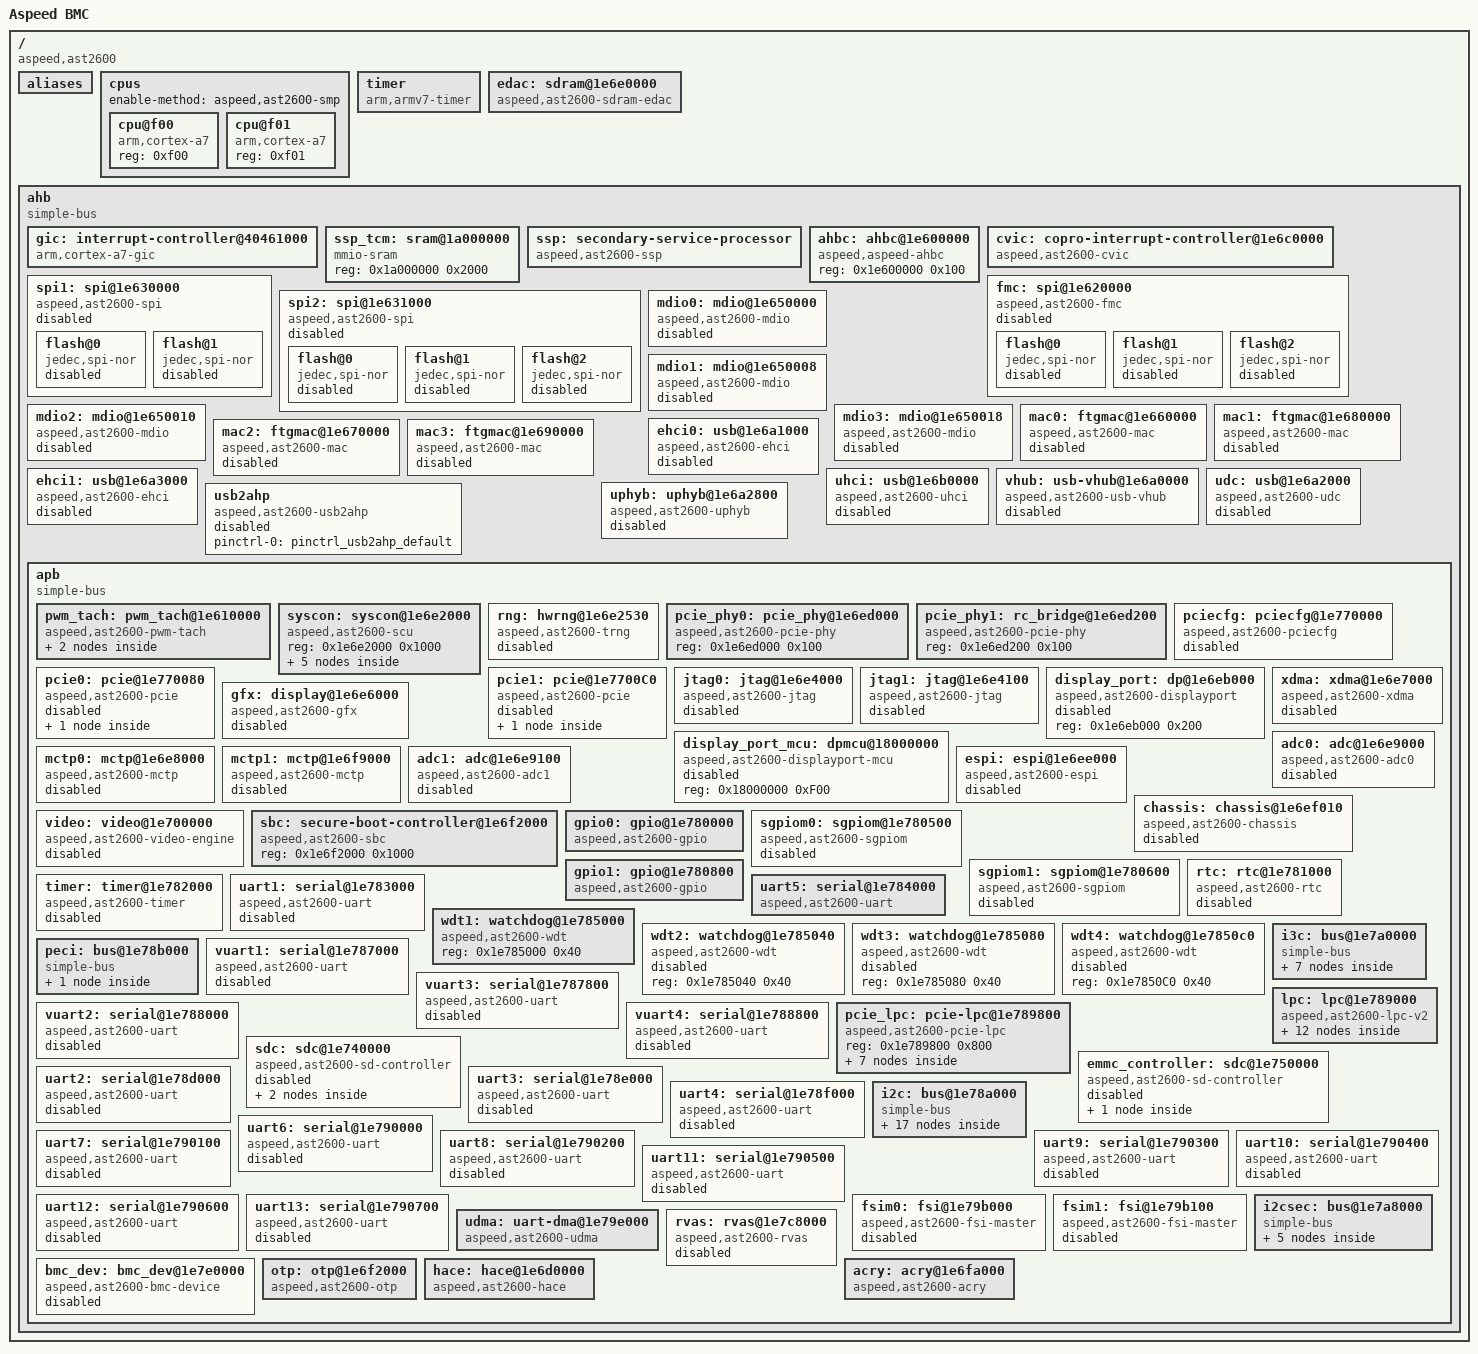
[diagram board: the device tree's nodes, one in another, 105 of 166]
// SPDX-License-Identifier: GPL-2.0-or-later
// Copyright 2019 IBM Corp.

#include <dt-bindings/interrupt-controller/arm-gic.h>
#include <dt-bindings/interrupt-controller/aspeed-scu-ic.h>
#include <dt-bindings/clock/ast2600-clock.h>

/ {
	model = "Aspeed BMC";
	compatible = "aspeed,ast2600";
	#address-cells = <1>;
	#size-cells = <1>;
	interrupt-parent = <&gic>;

	aliases {
		i3c0 = &i3c0;
		i3c1 = &i3c1;
		i3c2 = &i3c2;
		i3c3 = &i3c3;
		i3c4 = &i3c4;
		i3c5 = &i3c5;
		i2c0 = &i2c0;
		i2c1 = &i2c1;
		i2c2 = &i2c2;
		i2c3 = &i2c3;
		i2c4 = &i2c4;
		i2c5 = &i2c5;
		i2c6 = &i2c6;
		i2c7 = &i2c7;
		i2c8 = &i2c8;
		i2c9 = &i2c9;
		i2c10 = &i2c10;
		i2c11 = &i2c11;
		i2c12 = &i2c12;
		i2c13 = &i2c13;
		i2c14 = &i2c14;
		i2c15 = &i2c15;
		serial0 = &uart1;
		serial1 = &uart2;
		serial2 = &uart3;
		serial3 = &uart4;
		serial4 = &uart5;
		serial5 = &uart6;
		serial6 = &uart7;
		serial7 = &uart8;
		serial8 = &uart9;
		serial9 = &uart10;
		serial10 = &uart11;
		serial11 = &uart12;
		serial12 = &uart13;
		serial13 = &vuart1;
		serial14 = &vuart2;
		serial15 = &vuart3;
		serial16 = &vuart4;
	};


	cpus {
		#address-cells = <1>;
		#size-cells = <0>;
		enable-method = "aspeed,ast2600-smp";

		cpu@f00 {
			compatible = "arm,cortex-a7";
			device_type = "cpu";
			reg = <0xf00>;
		};

		cpu@f01 {
			compatible = "arm,cortex-a7";
			device_type = "cpu";
			reg = <0xf01>;
		};
	};

	timer {
		compatible = "arm,armv7-timer";
		interrupt-parent = <&gic>;
		interrupts = <GIC_PPI 13 (GIC_CPU_MASK_SIMPLE(2) | IRQ_TYPE_LEVEL_LOW)>,
			     <GIC_PPI 14 (GIC_CPU_MASK_SIMPLE(2) | IRQ_TYPE_LEVEL_LOW)>,
			     <GIC_PPI 11 (GIC_CPU_MASK_SIMPLE(2) | IRQ_TYPE_LEVEL_LOW)>,
			     <GIC_PPI 10 (GIC_CPU_MASK_SIMPLE(2) | IRQ_TYPE_LEVEL_LOW)>;
		arm,cpu-registers-not-fw-configured;
		always-on;
	};

	edac: sdram@1e6e0000 {
		compatible = "aspeed,ast2600-sdram-edac", "syscon";
		reg = <0x1e6e0000 0x174>;
		interrupts = <GIC_SPI 0 IRQ_TYPE_LEVEL_HIGH>;
	};

	ahb {
		compatible = "simple-bus";
		#address-cells = <1>;
		#size-cells = <1>;
		device_type = "soc";
		ranges;

		gic: interrupt-controller@40461000 {
			compatible = "arm,cortex-a7-gic";
			interrupts = <GIC_PPI 9 (GIC_CPU_MASK_SIMPLE(2) | IRQ_TYPE_LEVEL_HIGH)>;
			#interrupt-cells = <3>;
			interrupt-controller;
			interrupt-parent = <&gic>;
			reg = <0x40461000 0x1000>,
			    <0x40462000 0x1000>,
			    <0x40464000 0x2000>,
			    <0x40466000 0x2000>;
		};

		ssp_tcm: sram@1a000000 {
			compatible = "mmio-sram";
			reg = <0x1a000000 0x2000>;
		};

		ssp: secondary-service-processor {
			compatible = "aspeed,ast2600-ssp";
			#address-cells = <2>;
			#size-cells = <0>;
			interrupts =	<GIC_SPI 182 IRQ_TYPE_LEVEL_HIGH>,
					<GIC_SPI 183 IRQ_TYPE_LEVEL_HIGH>,
					<GIC_SPI 184 IRQ_TYPE_LEVEL_HIGH>,
					<GIC_SPI 185 IRQ_TYPE_LEVEL_HIGH>,
					<GIC_SPI 186 IRQ_TYPE_LEVEL_HIGH>,
					<GIC_SPI 187 IRQ_TYPE_LEVEL_HIGH>,
					<GIC_SPI 188 IRQ_TYPE_LEVEL_HIGH>,
					<GIC_SPI 189 IRQ_TYPE_LEVEL_HIGH>,
					<GIC_SPI 190 IRQ_TYPE_LEVEL_HIGH>,
					<GIC_SPI 191 IRQ_TYPE_LEVEL_HIGH>,
					<GIC_SPI 192 IRQ_TYPE_LEVEL_HIGH>,
					<GIC_SPI 193 IRQ_TYPE_LEVEL_HIGH>,
					<GIC_SPI 194 IRQ_TYPE_LEVEL_HIGH>,
					<GIC_SPI 195 IRQ_TYPE_LEVEL_HIGH>,
					<GIC_SPI 196 IRQ_TYPE_LEVEL_HIGH>;
			aspeed,cvic = <&cvic>;
			aspeed,scu = <&syscon>;
		};

		ahbc: ahbc@1e600000 {
			compatible = "aspeed,aspeed-ahbc", "syscon";
			reg = < 0x1e600000 0x100>;
		};

		cvic: copro-interrupt-controller@1e6c0000 {
			compatible = "aspeed,ast2600-cvic", "aspeed-cvic";
			valid-sources = <0xffffffff>;
			copro-sw-interrupts = <1>;
			reg = <0x1e6c0000 0x80>;
		};

		fmc: spi@1e620000 {
#if 1
			reg = <0x1e620000 0xc4>,
				<0x20000000 0x10000000>;
			reg-names = "spi_ctrl_reg", "spi_mmap";
			compatible = "aspeed,ast2600-fmc";
#else
			/* reg : cs0 : cs1 : cs2 */
			reg = <0x1e620000 0x100
				0x20000000 0x200000
				0x24000000 0x200000
				0x28000000 0x200000>;
			compatible = "aspeed,ast2600-fmc-spi";
			number_of_chip_select = /bits/ 16 <3>;
#endif
			#address-cells = <1>;
			#size-cells = <0>;
			clocks = <&syscon ASPEED_CLK_AHB>;
			status = "disabled";
			interrupts = <GIC_SPI 39 IRQ_TYPE_LEVEL_HIGH>;
			num-cs = <3>;
			flash@0 {
				reg = < 0 >;
				compatible = "jedec,spi-nor";
				spi-max-frequency = <50000000>;
				spi-rx-bus-width = <2>;
				status = "disabled";
			};
			flash@1 {
				reg = < 1 >;
				compatible = "jedec,spi-nor";
				spi-max-frequency = <50000000>;
				spi-rx-bus-width = <2>;
				status = "disabled";
			};
			flash@2 {
				reg = < 2 >;
				compatible = "jedec,spi-nor";
				spi-max-frequency = <50000000>;
				spi-rx-bus-width = <2>;
				status = "disabled";
			};
		};

		spi1: spi@1e630000 {
#if 1
			reg = <0x1e630000 0xc4>,
				<0x30000000 0x10000000>;
			reg-names = "spi_ctrl_reg", "spi_mmap";
			compatible = "aspeed,ast2600-spi";
#else
			/* reg : cs0 : cs1 */
			reg = <0x1e630000 0x100
				0x30000000 0x200000
				0x32000000 0x200000>;
			compatible = "aspeed,ast2600-fmc-spi";
			number_of_chip_select = /bits/ 16 <2>;
#endif
			#address-cells = <1>;
			#size-cells = <0>;
			clocks = <&syscon ASPEED_CLK_AHB>;
			num-cs = <2>;
			interrupts = <GIC_SPI 65 IRQ_TYPE_LEVEL_HIGH>;
			status = "disabled";
			flash@0 {
				reg = < 0 >;
				compatible = "jedec,spi-nor";
				spi-max-frequency = <50000000>;
				spi-rx-bus-width = <2>;
				status = "disabled";
			};
			flash@1 {
				reg = < 1 >;
				compatible = "jedec,spi-nor";
				spi-max-frequency = <50000000>;
				spi-rx-bus-width = <2>;
				status = "disabled";
			};
		};

		spi2: spi@1e631000 {
#if 1
			reg = < 0x1e631000 0xc4>,
				<0x50000000 0x10000000>;
			reg-names = "spi_ctrl_reg", "spi_mmap";
			compatible = "aspeed,ast2600-spi";
#else
			/* reg : cs0 : cs1 */
			reg = <0x1e631000 0x100
				0x50000000 0x200000
				0x52000000 0x200000
				0x54000000 0x200000>;
			compatible = "aspeed,ast2600-fmc-spi";
			number_of_chip_select = /bits/ 16 <3>;
#endif
			#address-cells = <1>;
			#size-cells = <0>;
			clocks = <&syscon ASPEED_CLK_AHB>;
			num-cs = <3>;
			interrupts = <GIC_SPI 65 IRQ_TYPE_LEVEL_HIGH>;
			status = "disabled";
			flash@0 {
				reg = < 0 >;
				compatible = "jedec,spi-nor";
				spi-max-frequency = <50000000>;
				spi-rx-bus-width = <2>;
				status = "disabled";
			};
			flash@1 {
				reg = < 1 >;
				compatible = "jedec,spi-nor";
				spi-max-frequency = <50000000>;
				spi-rx-bus-width = <2>;
				status = "disabled";
			};
			flash@2 {
				reg = < 2 >;
				compatible = "jedec,spi-nor";
				spi-max-frequency = <50000000>;
				spi-rx-bus-width = <2>;
				status = "disabled";
			};
		};

		mdio0: mdio@1e650000 {
			compatible = "aspeed,ast2600-mdio";
			reg = <0x1e650000 0x8>;
			#address-cells = <1>;
			#size-cells = <0>;
			status = "disabled";
			pinctrl-names = "default";
			pinctrl-0 = <&pinctrl_mdio1_default>;
			resets = <&syscon ASPEED_RESET_MII>;
		};

		mdio1: mdio@1e650008 {
			compatible = "aspeed,ast2600-mdio";
			reg = <0x1e650008 0x8>;
			#address-cells = <1>;
			#size-cells = <0>;
			status = "disabled";
			pinctrl-names = "default";
			pinctrl-0 = <&pinctrl_mdio2_default>;
			resets = <&syscon ASPEED_RESET_MII>;
		};

		mdio2: mdio@1e650010 {
			compatible = "aspeed,ast2600-mdio";
			reg = <0x1e650010 0x8>;
			#address-cells = <1>;
			#size-cells = <0>;
			status = "disabled";
			pinctrl-names = "default";
			pinctrl-0 = <&pinctrl_mdio3_default>;
			resets = <&syscon ASPEED_RESET_MII>;
		};

		mdio3: mdio@1e650018 {
			compatible = "aspeed,ast2600-mdio";
			reg = <0x1e650018 0x8>;
			#address-cells = <1>;
			#size-cells = <0>;
			status = "disabled";
			pinctrl-names = "default";
			pinctrl-0 = <&pinctrl_mdio4_default>;
			resets = <&syscon ASPEED_RESET_MII>;
		};

		mac0: ftgmac@1e660000 {
			compatible = "aspeed,ast2600-mac", "faraday,ftgmac100";
			reg = <0x1e660000 0x180>;
			#address-cells = <1>;
			#size-cells = <0>;
			interrupts = <GIC_SPI 2 IRQ_TYPE_LEVEL_HIGH>;
			clocks = <&syscon ASPEED_CLK_GATE_MAC1CLK>;
			resets = <&syscon ASPEED_RESET_MAC1>;
			status = "disabled";
		};

		mac1: ftgmac@1e680000 {
			compatible = "aspeed,ast2600-mac", "faraday,ftgmac100";
			reg = <0x1e680000 0x180>;
			#address-cells = <1>;
			#size-cells = <0>;
			interrupts = <GIC_SPI 3 IRQ_TYPE_LEVEL_HIGH>;
			clocks = <&syscon ASPEED_CLK_GATE_MAC2CLK>;
			resets = <&syscon ASPEED_RESET_MAC2>;
			status = "disabled";
		};

		mac2: ftgmac@1e670000 {
			compatible = "aspeed,ast2600-mac", "faraday,ftgmac100";
			reg = <0x1e670000 0x180>;
			#address-cells = <1>;
			#size-cells = <0>;
			interrupts = <GIC_SPI 32 IRQ_TYPE_LEVEL_HIGH>;
			clocks = <&syscon ASPEED_CLK_GATE_MAC3CLK>;
			resets = <&syscon ASPEED_RESET_MAC3>;
			status = "disabled";
		};

		mac3: ftgmac@1e690000 {
			compatible = "aspeed,ast2600-mac", "faraday,ftgmac100";
			reg = <0x1e690000 0x180>;
			#address-cells = <1>;
			#size-cells = <0>;
			interrupts = <GIC_SPI 33 IRQ_TYPE_LEVEL_HIGH>;
			clocks = <&syscon ASPEED_CLK_GATE_MAC4CLK>;
			resets = <&syscon ASPEED_RESET_MAC4>;
			status = "disabled";
		};

		ehci0: usb@1e6a1000 {
			compatible = "aspeed,ast2600-ehci", "generic-ehci";
			reg = <0x1e6a1000 0x100>;
			interrupts = <GIC_SPI 5 IRQ_TYPE_LEVEL_HIGH>;
			clocks = <&syscon ASPEED_CLK_GATE_USBPORT1CLK>;
			pinctrl-names = "default";
			pinctrl-0 = <&pinctrl_usb2ah_default>;
			status = "disabled";
		};

		ehci1: usb@1e6a3000 {
			compatible = "aspeed,ast2600-ehci", "generic-ehci";
			reg = <0x1e6a3000 0x100>;
			interrupts = <GIC_SPI 9 IRQ_TYPE_LEVEL_HIGH>;
			clocks = <&syscon ASPEED_CLK_GATE_USBPORT2CLK>;
			pinctrl-names = "default";
			pinctrl-0 = <&pinctrl_usb2bh_default>;
			status = "disabled";
		};

		uhci: usb@1e6b0000 {
			compatible = "aspeed,ast2600-uhci", "generic-uhci";
			reg = <0x1e6b0000 0x100>;
			interrupts = <GIC_SPI 10 IRQ_TYPE_LEVEL_HIGH>;
			#ports = <2>;
			clocks = <&syscon ASPEED_CLK_GATE_USBUHCICLK>;
			status = "disabled";
			/*
			 * No default pinmux, it will follow EHCI, use an
			 * explicit pinmux override if EHCI is not enabled.
			 */
		};

		vhub: usb-vhub@1e6a0000 {
			compatible = "aspeed,ast2600-usb-vhub";
			reg = <0x1e6a0000 0x350>;
			interrupts = <GIC_SPI 5 IRQ_TYPE_LEVEL_HIGH>;
			clocks = <&syscon ASPEED_CLK_GATE_USBPORT1CLK>;
			aspeed,vhub-downstream-ports = <7>;
			aspeed,vhub-generic-endpoints = <21>;
			pinctrl-names = "default";
			pinctrl-0 = <&pinctrl_usb2ad_default>;
			status = "disabled";
		};

		usb2ahp: usb2ahp {
			compatible = "aspeed,ast2600-usb2ahp";
			pinctrl-names = "default";
			pinctrl-0 = <&pinctrl_usb2ahp_default>;
			status = "disabled";
		};

		udc: usb@1e6a2000 {
			compatible = "aspeed,ast2600-udc";
			reg = <0x1e6a2000 0x300>;
			interrupts = <GIC_SPI 9 IRQ_TYPE_LEVEL_HIGH>;
			clocks = <&syscon ASPEED_CLK_GATE_USBPORT2CLK>;
			pinctrl-names = "default";
			pinctrl-0 = <&pinctrl_usb2bd_default>;
			status = "disabled";
		};

		uphyb: uphyb@1e6a2800 {
			compatible = "aspeed,ast2600-uphyb";
			reg = <0x1e6a2800 0x10>;
			ctrl = <0x0 0x100>;	/* <offset, value> */
			aspeed,scu = <&syscon>;
			status = "disabled";
		};

		apb {
			compatible = "simple-bus";
			#address-cells = <1>;
			#size-cells = <1>;
			ranges;

			pwm_tach: pwm_tach@1e610000 {
				compatible = "aspeed,ast2600-pwm-tach", "simple-mfd", "syscon";
				reg = <0x1e610000 0x100>;
				clocks = <&syscon ASPEED_CLK_AHB>;
				resets = <&syscon ASPEED_RESET_PWM>;

				pwm: pwm {
					compatible = "aspeed,ast2600-pwm";
					#pwm-cells = <3>;
					#address-cells = <1>;
					#size-cells = <0>;
					status = "disabled";
				};

				tach: tach {
					compatible = "aspeed,ast2600-tach";
					#address-cells = <1>;
					#size-cells = <0>;
					status = "disabled";
				};
			};

			syscon: syscon@1e6e2000 {
				compatible = "aspeed,ast2600-scu", "syscon", "simple-mfd";
				reg = <0x1e6e2000 0x1000>;
				ranges = <0 0x1e6e2000 0x1000>;
				#address-cells = <1>;
				#size-cells = <1>;
				#clock-cells = <1>;
				#reset-cells = <1>;

				pinctrl: pinctrl {
					compatible = "aspeed,ast2600-pinctrl";
				};

				silicon-id@14 {
					compatible = "aspeed,ast2600-silicon-id", "aspeed,silicon-id";
					reg = <0x14 0x4 0x5b0 0x8>;
				};

				smp-memram@180 {
					compatible = "aspeed,ast2600-smpmem";
					reg = <0x180 0x40>;
				};

				scu_ic0: interrupt-controller@560 {
					#interrupt-cells = <1>;
					compatible = "aspeed,ast2600-scu-ic0";
					reg = <0x560 0x4>;
					interrupts = <GIC_SPI 12 IRQ_TYPE_LEVEL_HIGH>;
					interrupt-controller;
				};

				scu_ic1: interrupt-controller@570 {
					#interrupt-cells = <1>;
					compatible = "aspeed,ast2600-scu-ic1";
					reg = <0x570 0x4>;
					interrupts = <GIC_SPI 41 IRQ_TYPE_LEVEL_HIGH>;
					interrupt-controller;
				};
			};

			rng: hwrng@1e6e2530 {
				compatible = "aspeed,ast2600-trng";
				reg = <0x1e6e2520 0x20>;
				aspeed,scu = <&syscon>;
				status = "disabled";
			};

			pcie_phy0: pcie_phy@1e6ed000 {
				compatible = "aspeed,ast2600-pcie-phy", "syscon";
				reg = <0x1e6ed000 0x100>;
			};

			pcie_phy1: rc_bridge@1e6ed200 {
				compatible = "aspeed,ast2600-pcie-phy", "syscon";
				reg = <0x1e6ed200 0x100>;
			};

			pciecfg: pciecfg@1e770000 {
				compatible = "aspeed,ast2600-pciecfg", "syscon";
				reg = <0x1e770000 0x80>;
				resets = <&syscon ASPEED_RESET_H2X>, <&syscon ASPEED_RESET_PCIE_DEV_O>, <&syscon ASPEED_RESET_PCIE_RC_O>;
				reset-names = "h2x", "rc_low", "rc_high";
				aspeed,ahbc = <&ahbc>;
				aspeed,pcie0 = <&pcie0>;
				aspeed,pcie1 = <&pcie1>;

				status = "disabled";
			};

			pcie0: pcie@1e770080 {
				compatible = "aspeed,ast2600-pcie";
				device_type = "pci";
				reg = <0x1e770080 0x40>;
				linux,pci-domain = <0>;
				#address-cells = <3>;
				#size-cells = <2>;
				interrupts = <GIC_SPI 167 IRQ_TYPE_LEVEL_HIGH>;
				bus-range = <0x00 0x7f>;
				ranges = <0x01000000 0 0x00000000 0x00000000 0x0 0x08000   /* I/O */
					0x02000000 0x0 0x60000000 0x60000000 0 0x10000000>; /* memory */

				status = "disabled";

				resets = <&syscon ASPEED_RESET_PCIE_DEV_O>;
				pinctrl-names = "default";
				pinctrl-0 = <&pinctrl_pcierc0_default>;

				#interrupt-cells = <1>;
				msi-parent = <&pcie0>;
				msi_address = <0x1e770058>;
				pciephy = <&pcie_phy0>;
				interrupt-map-mask = <0 0 0 7>;
				interrupt-map = <0 0 0 1 &pcie_intc0 0>,
						<0 0 0 2 &pcie_intc0 1>,
						<0 0 0 3 &pcie_intc0 2>,
						<0 0 0 4 &pcie_intc0 3>;
				pcie_intc0: interrupt-controller {
					interrupt-controller;
					#address-cells = <0>;
					#interrupt-cells = <1>;
				};
			};

			pcie1: pcie@1e7700C0 {
				compatible = "aspeed,ast2600-pcie";
				device_type = "pci";
				reg = <0x1e7700C0 0x40>;
				linux,pci-domain = <1>;
				#address-cells = <3>;
				#size-cells = <2>;
				interrupts = <GIC_SPI 168 IRQ_TYPE_LEVEL_HIGH>;
				bus-range = <0x80 0xff>;

				ranges = <0x01000000 0 0x00018000 0x00018000 0x0 0x08000
					0x02000000 0x0 0x70000000 0x70000000 0 0x10000000>; /* memory */

				status = "disabled";

				resets = <&syscon ASPEED_RESET_PCIE_RC_O>;
				pinctrl-names = "default";
				pinctrl-0 = <&pinctrl_pcierc1_default>;

				#interrupt-cells = <1>;
				msi-parent = <&pcie1>;
				msi_address = <0x1e77005C>;
				pciephy = <&pcie_phy1>;
				interrupt-map-mask = <0 0 0 7>;
				interrupt-map = <0 0 0 1 &pcie_intc1 0>,
						<0 0 0 2 &pcie_intc1 1>,
						<0 0 0 3 &pcie_intc1 2>,
						<0 0 0 4 &pcie_intc1 3>;
				pcie_intc1: interrupt-controller {
					interrupt-controller;
					#address-cells = <0>;
					#interrupt-cells = <1>;
				};
			};

			jtag0: jtag@1e6e4000 {
				compatible = "aspeed,ast2600-jtag";
				reg= <0x1e6e4000 0x20>;
				interrupts = <GIC_SPI 27 IRQ_TYPE_LEVEL_HIGH>;
				clocks = <&syscon ASPEED_CLK_AHB>;
				resets = <&syscon ASPEED_RESET_JTAG_MASTER>;
				status = "disabled";
			};

			jtag1: jtag@1e6e4100 {
				compatible = "aspeed,ast2600-jtag";
				reg= <0x1e6e4100 0x20>;
				interrupts = <GIC_SPI 53 IRQ_TYPE_LEVEL_HIGH>;
				clocks = <&syscon ASPEED_CLK_AHB>;
				resets = <&syscon ASPEED_RESET_JTAG_MASTER2>;
				pinctrl-names = "default";
				pinctrl-0 = <&pinctrl_jtagm_default>;
				status = "disabled";
			};

			display_port: dp@1e6eb000 {
				compatible = "aspeed,ast2600-displayport", "syscon";
				reg = <0x1e6eb000 0x200>;
				status = "disabled";
			};

			display_port_mcu: dpmcu@18000000 {
				compatible = "aspeed,ast2600-displayport-mcu", "syscon";
				reg = <0x18000000 0xF00>;
				status = "disabled";
			};

			gfx: display@1e6e6000 {
				compatible = "aspeed,ast2600-gfx", "syscon";
				reg = <0x1e6e6000 0x1000>;
				reg-io-width = <4>;
				clocks = <&syscon ASPEED_CLK_GATE_D1CLK>;
				resets = <&syscon ASPEED_RESET_CRT>,
				<&syscon ASPEED_RESET_GRAPHICS>;
				reset-names = "crt", "engine";
				syscon = <&syscon>;
				interrupts-extended = <&gic GIC_SPI 14 IRQ_TYPE_LEVEL_HIGH>,
				<&scu_ic0 ASPEED_AST2600_SCU_IC0_PCIE_PERST_LO_TO_HI>,
				<&scu_ic0 ASPEED_AST2600_SCU_IC0_PCIE_PERST_HI_TO_LO>;
				status = "disabled";
			};

			xdma: xdma@1e6e7000 {
				compatible = "aspeed,ast2600-xdma";
				reg = <0x1e6e7000 0x100>;
				clocks = <&syscon ASPEED_CLK_GATE_BCLK>;
				resets = <&syscon ASPEED_RESET_DEV_XDMA>, <&syscon ASPEED_RESET_RC_XDMA>;
				reset-names = "device", "root-complex";
				interrupts-extended = <&gic GIC_SPI 6 IRQ_TYPE_LEVEL_HIGH>,
						      <&scu_ic0 ASPEED_AST2600_SCU_IC0_PCIE_PERST_LO_TO_HI>;
				aspeed,pcie-device = "bmc";
				aspeed,scu = <&syscon>;
				status = "disabled";
			};

			mctp0: mctp@1e6e8000 {
				compatible = "aspeed,ast2600-mctp";
				reg = <0x1e6e8000 0x30>;
				interrupts-extended = <&gic GIC_SPI 26 IRQ_TYPE_LEVEL_HIGH>, <&scu_ic0 ASPEED_AST2600_SCU_IC0_PCIE_PERST_LO_TO_HI>;
				interrupt-names = "mctp", "pcie";
				resets = <&syscon ASPEED_RESET_DEV_MCTP>;
				aspeed,scu = <&syscon>;
				aspeed,pcieh = <&pcie_phy0>;
				status = "disabled";
			};

			mctp1: mctp@1e6f9000 {
				compatible = "aspeed,ast2600-mctp";
				reg = <0x1e6f9000 0x30>;
				interrupts-extended = <&scu_ic0 ASPEED_AST2600_SCU_IC0_PCIE_RCRST_LO_TO_HI>;
				interrupt-names = "pcie";
				pcie_rc;
				resets = <&syscon ASPEED_RESET_RC_MCTP>, <&syscon ASPEED_RESET_DEV_MCTP>;
				aspeed,scu = <&syscon>;
				aspeed,pcieh = <&pcie_phy1>;
				status = "disabled";
			};

			adc0: adc@1e6e9000 {
				compatible = "aspeed,ast2600-adc0";
				reg = <0x1e6e9000 0x100>;
				clocks = <&syscon ASPEED_CLK_APB2>;
				resets = <&syscon ASPEED_RESET_ADC>;
				interrupts = <GIC_SPI 46 IRQ_TYPE_LEVEL_HIGH>;
				#io-channel-cells = <1>;
				status = "disabled";
			};

			adc1: adc@1e6e9100 {
				compatible = "aspeed,ast2600-adc1";
				reg = <0x1e6e9100 0x100>;
				clocks = <&syscon ASPEED_CLK_APB2>;
				resets = <&syscon ASPEED_RESET_ADC>;
				interrupts = <GIC_SPI 46 IRQ_TYPE_LEVEL_HIGH>;
				#io-channel-cells = <1>;
				status = "disabled";
			};

			espi: espi@1e6ee000 {
				compatible = "aspeed,ast2600-espi";
				reg = <0x1e6ee000 0x1000>;
				interrupts = <GIC_SPI 42 IRQ_TYPE_LEVEL_HIGH>,
					     <GIC_SPI 108 IRQ_TYPE_LEVEL_HIGH>;
				clocks = <&syscon ASPEED_CLK_GATE_ESPICLK>;
				status = "disabled";
			};

			chassis: chassis@1e6ef010 {
				compatible = "aspeed,ast2600-chassis";
				reg = <0x1e6ef010 0x4>;
				interrupts = <GIC_SPI 149 IRQ_TYPE_LEVEL_HIGH>;
				status = "disabled";
			};

			video: video@1e700000 {
				compatible = "aspeed,ast2600-video-engine";
				reg = <0x1e700000 0x1000>;
				clocks = <&syscon ASPEED_CLK_GATE_VCLK>,
					 <&syscon ASPEED_CLK_GATE_ECLK>;
				clock-names = "vclk", "eclk";
				interrupts = <GIC_SPI 7 IRQ_TYPE_LEVEL_HIGH>;
				resets = <&syscon ASPEED_RESET_VIDEO>;
				status = "disabled";
			};

			sbc: secure-boot-controller@1e6f2000 {
				compatible = "aspeed,ast2600-sbc";
				reg = <0x1e6f2000 0x1000>;
			};

			gpio0: gpio@1e780000 {
				#gpio-cells = <2>;
				gpio-controller;
				compatible = "aspeed,ast2600-gpio";
				reg = <0x1e780000 0x400>;
				interrupts = <GIC_SPI 40 IRQ_TYPE_LEVEL_HIGH>;
				gpio-ranges = <&pinctrl 0 0 208>;
				ngpios = <208>;
				clocks = <&syscon ASPEED_CLK_APB2>;
				interrupt-controller;
				#interrupt-cells = <2>;
			};

			sgpiom0: sgpiom@1e780500 {
				#gpio-cells = <2>;
				gpio-controller;
				compatible = "aspeed,ast2600-sgpiom";
				reg = <0x1e780500 0x100>;
				interrupts = <GIC_SPI 51 IRQ_TYPE_LEVEL_HIGH>;
				clocks = <&syscon ASPEED_CLK_APB2>;
				interrupt-controller;
				bus-frequency = <12000000>;
				pinctrl-names = "default";
				pinctrl-0 = <&pinctrl_sgpm1_default>;
				status = "disabled";
			};

			sgpiom1: sgpiom@1e780600 {
				#gpio-cells = <2>;
				gpio-controller;
				compatible = "aspeed,ast2600-sgpiom";
				reg = <0x1e780600 0x100>;
				interrupts = <GIC_SPI 70 IRQ_TYPE_LEVEL_HIGH>;
				clocks = <&syscon ASPEED_CLK_APB2>;
				interrupt-controller;
				bus-frequency = <12000000>;
				pinctrl-names = "default";
				pinctrl-0 = <&pinctrl_sgpm2_default>;
				status = "disabled";
			};

			gpio1: gpio@1e780800 {
				#gpio-cells = <2>;
				gpio-controller;
				compatible = "aspeed,ast2600-gpio";
				reg = <0x1e780800 0x800>;
				interrupts = <GIC_SPI 11 IRQ_TYPE_LEVEL_HIGH>;
				gpio-ranges = <&pinctrl 0 208 36>;
				ngpios = <36>;
				clocks = <&syscon ASPEED_CLK_APB1>;
				interrupt-controller;
				#interrupt-cells = <2>;
			};

			rtc: rtc@1e781000 {
				compatible = "aspeed,ast2600-rtc";
				reg = <0x1e781000 0x18>;
				interrupts = <GIC_SPI 13 IRQ_TYPE_LEVEL_HIGH>;
				status = "disabled";
			};

			timer: timer@1e782000 {
				compatible = "aspeed,ast2600-timer";
				reg = <0x1e782000 0x90>;
				interrupts-extended = <&gic  GIC_SPI 16 IRQ_TYPE_LEVEL_HIGH>,
						<&gic  GIC_SPI 17 IRQ_TYPE_LEVEL_HIGH>,
						<&gic  GIC_SPI 18 IRQ_TYPE_LEVEL_HIGH>,
						<&gic  GIC_SPI 19 IRQ_TYPE_LEVEL_HIGH>,
						<&gic  GIC_SPI 20 IRQ_TYPE_LEVEL_HIGH>,
						<&gic  GIC_SPI 21 IRQ_TYPE_LEVEL_HIGH>,
						<&gic  GIC_SPI 22 IRQ_TYPE_LEVEL_HIGH>,
						<&gic  GIC_SPI 23 IRQ_TYPE_LEVEL_HIGH>;
				clocks = <&syscon ASPEED_CLK_APB1>;
				clock-names = "PCLK";
				status = "disabled";
                        };

			uart1: serial@1e783000 {
				compatible = "aspeed,ast2600-uart";
				reg = <0x1e783000 0x20>;
				reg-shift = <2>;
				reg-io-width = <4>;
				interrupts = <GIC_SPI 47 IRQ_TYPE_LEVEL_HIGH>;
				clocks = <&syscon ASPEED_CLK_GATE_UART1CLK>;
				resets = <&lpc_reset 4>;
				no-loopback-test;
				pinctrl-names = "default";
				pinctrl-0 = <&pinctrl_txd1_default &pinctrl_rxd1_default>;
				status = "disabled";
			};

			uart5: serial@1e784000 {
				compatible = "aspeed,ast2600-uart";
				reg = <0x1e784000 0x1000>;
				reg-shift = <2>;
				interrupts = <GIC_SPI 8 IRQ_TYPE_LEVEL_HIGH>;
				clocks = <&syscon ASPEED_CLK_GATE_UART5CLK>;
				no-loopback-test;
			};

			wdt1: watchdog@1e785000 {
				compatible = "aspeed,ast2600-wdt";
				reg = <0x1e785000 0x40>;
			};

			wdt2: watchdog@1e785040 {
				compatible = "aspeed,ast2600-wdt";
				reg = <0x1e785040 0x40>;
				status = "disabled";
			};

			wdt3: watchdog@1e785080 {
				compatible = "aspeed,ast2600-wdt";
				reg = <0x1e785080 0x40>;
				status = "disabled";
			};

			wdt4: watchdog@1e7850c0 {
				compatible = "aspeed,ast2600-wdt";
				reg = <0x1e7850C0 0x40>;
				status = "disabled";
			};

			i3c: bus@1e7a0000 {
				compatible = "simple-bus";
				#address-cells = <1>;
				#size-cells = <1>;
				ranges = <0 0x1e7a0000 0x8000>;
			};

			peci: bus@1e78b000 {
				compatible = "simple-bus";
				#address-cells = <1>;
				#size-cells = <1>;
				ranges = <0x0 0x1e78b000 0x100>;
			};

			vuart1: serial@1e787000 {
				compatible = "aspeed,ast2600-uart";
				reg = <0x1e787000 0x40>;
				interrupts = <GIC_SPI 147 IRQ_TYPE_LEVEL_HIGH>;
				clocks = <&syscon ASPEED_CLK_APB1>;
				virtual;
				status = "disabled";
			};

			vuart3: serial@1e787800 {
				compatible = "aspeed,ast2600-uart";
				reg = <0x1e787800 0x40>;
				interrupts = <GIC_SPI 180 IRQ_TYPE_LEVEL_HIGH>;
				clocks = <&syscon ASPEED_CLK_APB1>;
				virtual;
				status = "disabled";
			};

			vuart2: serial@1e788000 {
				compatible = "aspeed,ast2600-uart";
				reg = <0x1e788000 0x40>;
				interrupts = <GIC_SPI 148 IRQ_TYPE_LEVEL_HIGH>;
				clocks = <&syscon ASPEED_CLK_APB1>;
				virtual;
				status = "disabled";
			};

			vuart4: serial@1e788800 {
				compatible = "aspeed,ast2600-uart";
				reg = <0x1e788800 0x40>;
				interrupts = <GIC_SPI 181 IRQ_TYPE_LEVEL_HIGH>;
				clocks = <&syscon ASPEED_CLK_APB2>;
				virtual;
				status = "disabled";
			};

			lpc: lpc@1e789000 {
				compatible = "aspeed,ast2600-lpc-v2", "simple-mfd", "syscon";
				reg = <0x1e789000 0x1000>;
				reg-io-width = <4>;

				#address-cells = <1>;
				#size-cells = <1>;
				ranges = <0x0 0x1e789000 0x1000>;

				kcs1: kcs1@24 {
					compatible = "aspeed,ast2600-kcs-bmc";
					reg = <0x0 0x130>;
					interrupts = <GIC_SPI 138 IRQ_TYPE_LEVEL_HIGH>;
					clocks = <&syscon ASPEED_CLK_GATE_LCLK>;
					kcs_chan = <1>;
					status = "disabled";
				};

				kcs2: kcs2@28 {
					compatible = "aspeed,ast2600-kcs-bmc";
					reg = <0x0 0x130>;
					interrupts = <GIC_SPI 139 IRQ_TYPE_LEVEL_HIGH>;
					kcs_chan = <2>;
					status = "disabled";
				};

				kcs3: kcs3@2c {
					compatible = "aspeed,ast2600-kcs-bmc";
					reg = <0x0 0x130>;
					interrupts = <GIC_SPI 140 IRQ_TYPE_LEVEL_HIGH>;
					kcs_chan = <3>;
					status = "disabled";
				};

				kcs4: kcs4@114 {
					compatible = "aspeed,ast2600-kcs-bmc";
					reg = <0x0 0x130>;
					interrupts = <GIC_SPI 141 IRQ_TYPE_LEVEL_HIGH>;
					kcs_chan = <4>;
					status = "disabled";
				};

				lpc_ctrl: lpc-ctrl@80 {
					compatible = "aspeed,ast2600-lpc-ctrl";
					reg = <0x80 0x80>;
					clocks = <&syscon ASPEED_CLK_GATE_LCLK>;
					status = "disabled";
				};

				lpc_snoop: lpc-snoop@80 {
					compatible = "aspeed,ast2600-lpc-snoop";
					reg = <0x80 0x80>;
					interrupts = <GIC_SPI 144 IRQ_TYPE_LEVEL_HIGH>;
					status = "disabled";
				};

				lpc_pcc: lpc-pcc@0 {
					compatible = "aspeed,ast2600-lpc-pcc";
					reg = <0x0 0x140>;
					interrupts = <GIC_SPI 145 IRQ_TYPE_LEVEL_HIGH>;
					status = "disabled";
				};

				lhc: lhc@a0 {
					compatible = "aspeed,ast2600-lhc";
					reg = <0xa0 0x24 0xc8 0x8>;
				};

				lpc_reset: reset-controller@98 {
					compatible = "aspeed,ast2600-lpc-reset";
					reg = <0x98 0x4>;
					#reset-cells = <1>;
				};

				uart_routing: uart-routing@98 {
					compatible = "aspeed,ast2600-uart-routing";
					reg = <0x98 0x8>;
					status = "disabled";
				};

				ibt: ibt@140 {
					compatible = "aspeed,ast2600-ibt-bmc";
					reg = <0x140 0x18>;
					interrupts = <GIC_SPI 143 IRQ_TYPE_LEVEL_HIGH>;
					clocks = <&syscon ASPEED_CLK_GATE_LCLK>;
					status = "disabled";
				};

				mbox: mbox@200 {
					compatible = "aspeed,ast2600-mbox";
					reg = <0x200 0xc0>;
					interrupts = <GIC_SPI 54 IRQ_TYPE_LEVEL_HIGH>;
					status = "disabled";
				};
			};

			pcie_lpc: pcie-lpc@1e789800 {
				compatible = "aspeed,ast2600-pcie-lpc", "simple-mfd", "syscon";
				reg = <0x1e789800 0x800>;

				#address-cells = <1>;
				#size-cells = <1>;
				ranges = <0x0 0x1e789800 0x800>;

				pcie_kcs1: pcie-kcs1@0 {
					compatible = "aspeed,ast2600-kcs-bmc";
					reg = <0x0 0x130>;
					interrupts = <GIC_SPI 174 IRQ_TYPE_LEVEL_HIGH>;
					kcs_chan = <5>;
					status = "disabled";
				};

				pcie_kcs2: pcie-kcs2@0 {
					compatible = "aspeed,ast2600-kcs-bmc";
					reg = <0x0 0x130>;
					interrupts = <GIC_SPI 175 IRQ_TYPE_LEVEL_HIGH>;
					kcs_chan = <6>;
					status = "disabled";
				};

				pcie_kcs3: pcie-kcs3@0 {
					compatible = "aspeed,ast2600-kcs-bmc";
					reg = <0x0 0x130>;
					interrupts = <GIC_SPI 176 IRQ_TYPE_LEVEL_HIGH>;
					kcs_chan = <7>;
					status = "disabled";
				};

				pcie_kcs4: pcie-kcs4@0 {
					compatible = "aspeed,ast2600-kcs-bmc";
					reg = <0x0 0x130>;
					interrupts = <GIC_SPI 177 IRQ_TYPE_LEVEL_HIGH>;
					kcs_chan = <8>;
					status = "disabled";
				};

				pcie_snoop: pcie-snoop@80 {
					compatible = "aspeed,ast2600-lpc-snoop";
					reg = <0x80 0x80>;
					interrupts = <GIC_SPI 171 IRQ_TYPE_LEVEL_HIGH>;
					status = "disabled";
				};

				pcie_pcc: pcie-pcc@0 {
					compatible = "aspeed,ast2600-lpc-pcc";
					reg = <0x0 0x140>;
					interrupts = <GIC_SPI 173 IRQ_TYPE_LEVEL_HIGH>;
					status = "disabled";
				};

				pcie_ibt: pcie_ibt@140 {
					compatible = "aspeed,ast2600-ibt-bmc";
					reg = <0x140 0x18>;
					interrupts = <GIC_SPI 172 IRQ_TYPE_LEVEL_HIGH>;
					status = "disabled";
				};

			};

			sdc: sdc@1e740000 {
				compatible = "aspeed,ast2600-sd-controller";
				reg = <0x1e740000 0x100>;
				#address-cells = <1>;
				#size-cells = <1>;
				ranges = <0 0x1e740000 0x10000>;
				clocks = <&syscon ASPEED_CLK_GATE_SDCLK>;
				status = "disabled";

				sdhci0: sdhci@1e740100 {
					compatible = "aspeed,ast2600-sdhci", "sdhci";
					reg = <0x100 0x100>;
					interrupts = <GIC_SPI 43 IRQ_TYPE_LEVEL_HIGH>;
					sdhci,auto-cmd12;
					sd-uhs-sdr50;
					clocks = <&syscon ASPEED_CLK_SDIO>;
					pinctrl-names = "default";
					pinctrl-0 = <&pinctrl_sd1_default>;
					status = "disabled";
				};

				sdhci1: sdhci@1e740200 {
					compatible = "aspeed,ast2600-sdhci", "sdhci";
					reg = <0x200 0x100>;
					interrupts = <GIC_SPI 43 IRQ_TYPE_LEVEL_HIGH>;
					sdhci,auto-cmd12;
					sd-uhs-sdr50;
					clocks = <&syscon ASPEED_CLK_SDIO>;
					pinctrl-names = "default";
					pinctrl-0 = <&pinctrl_sd2_default>;
					status = "disabled";
				};
			};

			emmc_controller: sdc@1e750000 {
				compatible = "aspeed,ast2600-sd-controller";
				reg = <0x1e750000 0x100>;
				#address-cells = <1>;
				#size-cells = <1>;
				ranges = <0 0x1e750000 0x10000>;
				clocks = <&syscon ASPEED_CLK_GATE_EMMCCLK>;
				resets = <&syscon ASPEED_RESET_EMMC>;
				status = "disabled";

				emmc: sdhci@1e750100 {
					compatible = "aspeed,ast2600-emmc";
					reg = <0x100 0x100>;
					sdhci,auto-cmd12;
					interrupts = <GIC_SPI 15 IRQ_TYPE_LEVEL_HIGH>;
					clocks = <&syscon ASPEED_CLK_EMMC>;
					pinctrl-names = "default";
					pinctrl-0 = <&pinctrl_emmc_default>;
					status = "disabled";
				};
			};

			uart2: serial@1e78d000 {
				compatible = "aspeed,ast2600-uart";
				reg = <0x1e78d000 0x20>;
				interrupts = <GIC_SPI 48 IRQ_TYPE_LEVEL_HIGH>;
				clocks = <&syscon ASPEED_CLK_GATE_UART2CLK>;
				resets = <&lpc_reset 5>;
				pinctrl-names = "default";
				pinctrl-0 = <&pinctrl_txd2_default &pinctrl_rxd2_default>;
				no-loopback-test;
				status = "disabled";
			};

			uart3: serial@1e78e000 {
				compatible = "aspeed,ast2600-uart";
				reg = <0x1e78e000 0x20>;
				interrupts = <GIC_SPI 49 IRQ_TYPE_LEVEL_HIGH>;
				clocks = <&syscon ASPEED_CLK_GATE_UART3CLK>;
				resets = <&lpc_reset 6>;
				pinctrl-names = "default";
				pinctrl-0 = <&pinctrl_txd3_default &pinctrl_rxd3_default>;
				no-loopback-test;
				status = "disabled";
			};

			uart4: serial@1e78f000 {
				compatible = "aspeed,ast2600-uart";
				reg = <0x1e78f000 0x20>;
				interrupts = <GIC_SPI 50 IRQ_TYPE_LEVEL_HIGH>;
				clocks = <&syscon ASPEED_CLK_GATE_UART4CLK>;
				resets = <&lpc_reset 7>;
				pinctrl-names = "default";
				pinctrl-0 = <&pinctrl_txd4_default &pinctrl_rxd4_default>;
				no-loopback-test;
				status = "disabled";
			};

			i2c: bus@1e78a000 {
				compatible = "simple-bus";
				#address-cells = <1>;
				#size-cells = <1>;
				ranges = <0 0x1e78a000 0x1000>;
			};

			uart6: serial@1e790000 {
				compatible = "aspeed,ast2600-uart";
				reg = <0x1e790000 0x20>;
				interrupts = <GIC_SPI 57 IRQ_TYPE_LEVEL_HIGH>;
				clocks = <&syscon ASPEED_CLK_GATE_UART6CLK>;
				pinctrl-names = "default";
				pinctrl-0 = <&pinctrl_uart6_default>;
				no-loopback-test;
				status = "disabled";
			};

			uart7: serial@1e790100 {
				compatible = "aspeed,ast2600-uart";
				reg = <0x1e790100 0x20>;
				interrupts = <GIC_SPI 58 IRQ_TYPE_LEVEL_HIGH>;
				clocks = <&syscon ASPEED_CLK_GATE_UART7CLK>;
				pinctrl-names = "default";
				pinctrl-0 = <&pinctrl_uart7_default>;
				no-loopback-test;
				status = "disabled";
			};

			uart8: serial@1e790200 {
				compatible = "aspeed,ast2600-uart";
				reg = <0x1e790200 0x20>;
				interrupts = <GIC_SPI 59 IRQ_TYPE_LEVEL_HIGH>;
				clocks = <&syscon ASPEED_CLK_GATE_UART8CLK>;
				pinctrl-names = "default";
				pinctrl-0 = <&pinctrl_uart8_default>;
				no-loopback-test;
				status = "disabled";
			};

			uart9: serial@1e790300 {
				compatible = "aspeed,ast2600-uart";
				reg = <0x1e790300 0x20>;
				interrupts = <GIC_SPI 60 IRQ_TYPE_LEVEL_HIGH>;
				clocks = <&syscon ASPEED_CLK_GATE_UART9CLK>;
				pinctrl-names = "default";
				pinctrl-0 = <&pinctrl_uart9_default>;
				no-loopback-test;
				status = "disabled";
			};

			uart10: serial@1e790400 {
				compatible = "aspeed,ast2600-uart";
				reg = <0x1e790400 0x20>;
				interrupts = <GIC_SPI 61 IRQ_TYPE_LEVEL_HIGH>;
				clocks = <&syscon ASPEED_CLK_GATE_UART10CLK>;
				pinctrl-names = "default";
				pinctrl-0 = <&pinctrl_uart10_default>;
				no-loopback-test;
				status = "disabled";
			};

			uart11: serial@1e790500 {
				compatible = "aspeed,ast2600-uart";
				reg = <0x1e790500 0x20>;
				interrupts = <GIC_SPI 62 IRQ_TYPE_LEVEL_HIGH>;
				clocks = <&syscon ASPEED_CLK_GATE_UART11CLK>;
				pinctrl-names = "default";
				pinctrl-0 = <&pinctrl_uart11_default>;
				no-loopback-test;
				status = "disabled";
			};

			uart12: serial@1e790600 {
				compatible = "aspeed,ast2600-uart";
				reg = <0x1e790600 0x20>;
				interrupts = <GIC_SPI 63 IRQ_TYPE_LEVEL_HIGH>;
				clocks = <&syscon ASPEED_CLK_GATE_UART12CLK>;
				pinctrl-names = "default";
				pinctrl-0 = <&pinctrl_uart12g1_default>;
				no-loopback-test;
				status = "disabled";
			};

			uart13: serial@1e790700 {
				compatible = "aspeed,ast2600-uart";
				reg = <0x1e790700 0x20>;
				interrupts = <GIC_SPI 64 IRQ_TYPE_LEVEL_HIGH>;
				clocks = <&syscon ASPEED_CLK_GATE_UART13CLK>;
				pinctrl-names = "default";
				pinctrl-0 = <&pinctrl_uart13g1_default>;
				no-loopback-test;
				status = "disabled";
			};

			fsim0: fsi@1e79b000 {
				compatible = "aspeed,ast2600-fsi-master", "fsi-master";
				reg = <0x1e79b000 0x94>;
				interrupts = <GIC_SPI 100 IRQ_TYPE_LEVEL_HIGH>;
				pinctrl-names = "default";
				pinctrl-0 = <&pinctrl_fsi1_default>;
				clocks = <&syscon ASPEED_CLK_GATE_FSICLK>;
				status = "disabled";
			};

			fsim1: fsi@1e79b100 {
				compatible = "aspeed,ast2600-fsi-master", "fsi-master";
				reg = <0x1e79b100 0x94>;
				interrupts = <GIC_SPI 101 IRQ_TYPE_LEVEL_HIGH>;
				pinctrl-names = "default";
				pinctrl-0 = <&pinctrl_fsi2_default>;
				clocks = <&syscon ASPEED_CLK_GATE_FSICLK>;
				status = "disabled";
			};

			udma: uart-dma@1e79e000 {
				compatible = "aspeed,ast2600-udma";
				reg = <0x1e79e000 0x400>;
				interrupts = <GIC_SPI 56 IRQ_TYPE_LEVEL_HIGH>;
			};

			i2csec: bus@1e7a8000 {
				compatible = "simple-bus";
				#address-cells = <1>;
				#size-cells = <1>;
				ranges = <0 0x1e7a8000 0x1000>;
			};

			rvas: rvas@1e7c8000 {
				compatible = "aspeed,ast2600-rvas";
				reg = <0x1e7c8000 0x800 0x1e6ec000 0x800 0x1e700000 0x1000>;
				clocks = <&syscon ASPEED_CLK_GATE_RVASCLK>,
					 <&syscon ASPEED_CLK_GATE_VCLK>,
					 <&syscon ASPEED_CLK_GATE_ECLK>;
				clock-names = "rvasclk-gate", "vclk", "eclk";
				interrupts = <GIC_SPI 98 IRQ_TYPE_LEVEL_HIGH>, <GIC_SPI 163 IRQ_TYPE_LEVEL_HIGH>, <GIC_SPI 7 IRQ_TYPE_LEVEL_HIGH>;
				resets = <&syscon ASPEED_RESET_RVAS>, <&syscon ASPEED_RESET_VIDEO>;
				status = "disabled";
			};

			bmc_dev: bmc_dev@1e7e0000 {
				compatible = "aspeed,ast2600-bmc-device";
				reg = <0x1e7e0000 0xB000>;
				interrupts-extended = <&gic GIC_SPI 99 IRQ_TYPE_LEVEL_HIGH>,
						      <&scu_ic0 ASPEED_AST2600_SCU_IC0_PCIE_PERST_LO_TO_HI>;
				aspeed,scu = <&syscon>;
				pcie2lpc;
				status = "disabled";
			};

			otp: otp@1e6f2000 {
				compatible = "aspeed,ast2600-otp";
				reg = <0x1e6f2000 0x940>;
				aspeed,scu = <&syscon>;
			};

			hace: hace@1e6d0000 {
				compatible = "aspeed,ast2600-hace";
				reg = <0x1e6d0000 0x200>;
				interrupts = <GIC_SPI 4 IRQ_TYPE_LEVEL_HIGH>;
				clocks = <&syscon ASPEED_CLK_GATE_YCLK>;
				clock-names = "yclk";
				resets = <&syscon ASPEED_RESET_HACE>;
				status = "ok";
			};

			acry: acry@1e6fa000 {
				compatible = "aspeed,ast2600-acry";
				reg = <0x1e6fa000 0x400 0x1e710000 0x1800>;
				interrupts = <GIC_SPI 160 IRQ_TYPE_LEVEL_HIGH>;
				clocks = <&syscon ASPEED_CLK_GATE_RSACLK>;
				clock-names = "rsaclk";
				aspeed,ahbc = <&ahbc>;
				status = "ok";
			};

		};
	};
};

#include "aspeed-g6-pinctrl.dtsi"

&peci {
	peci0: peci-bus@0 {
		compatible = "aspeed,ast2600-peci";
		reg = <0x0 0x100>;
		#address-cells = <1>;
		#size-cells = <0>;
		interrupts = <GIC_SPI 38 IRQ_TYPE_LEVEL_HIGH>;
		clocks = <&syscon ASPEED_CLK_GATE_REF0CLK>,
			<&syscon ASPEED_CLK_AHB>;
		clock-names = "ref-clk", "hclk";
		clock-sel-hclk;
		resets = <&syscon ASPEED_RESET_PECI>;
		clock-frequency = <12000>;
		rd-sampling-point = <8>;
		cmd-timeout-ms = <1000>;
		status = "disabled";
	};
};

&i2c {

	i2c_gr: i2c-global-regs@0 {
		compatible = "aspeed,ast2600-i2c-global", "syscon";
		reg = <0x0 0x20>;
		clocks = <&syscon ASPEED_CLK_APB2>;
		resets = <&syscon ASPEED_RESET_I2C>;
	};

	i2c0: i2c-bus@80 {
		#address-cells = <1>;
		#size-cells = <0>;
		#interrupt-cells = <1>;
		reg = <0x80 0x80>, <0xC00 0x20>;
		compatible = "aspeed,ast2600-i2c-bus";
		clocks = <&syscon ASPEED_CLK_APB2>;
		resets = <&syscon ASPEED_RESET_I2C>;
		interrupts = <GIC_SPI 110 IRQ_TYPE_LEVEL_HIGH>;
		bus-frequency = <100000>;
		buff-mode;
		pinctrl-names = "default";
		pinctrl-0 = <&pinctrl_i2c1_default>;
		status = "disabled";
	};

	i2c1: i2c-bus@100 {
		#address-cells = <1>;
		#size-cells = <0>;
		#interrupt-cells = <1>;
		reg = <0x100 0x80>, <0xC20 0x20>;
		compatible = "aspeed,ast2600-i2c-bus";
		clocks = <&syscon ASPEED_CLK_APB2>;
		resets = <&syscon ASPEED_RESET_I2C>;
		interrupts = <GIC_SPI 111 IRQ_TYPE_LEVEL_HIGH>;
		bus-frequency = <100000>;
		buff-mode;
		pinctrl-names = "default";
		pinctrl-0 = <&pinctrl_i2c2_default>;
		status = "disabled";
	};

	i2c2: i2c-bus@180 {
		#address-cells = <1>;
		#size-cells = <0>;
		#interrupt-cells = <1>;
		reg = <0x180 0x80>, <0xC40 0x20>;
		compatible = "aspeed,ast2600-i2c-bus";
		clocks = <&syscon ASPEED_CLK_APB2>;
		resets = <&syscon ASPEED_RESET_I2C>;
		interrupts = <GIC_SPI 112 IRQ_TYPE_LEVEL_HIGH>;
		bus-frequency = <100000>;
		buff-mode;
		pinctrl-names = "default";
		pinctrl-0 = <&pinctrl_i2c3_default>;
		status = "disabled";
	};

	i2c3: i2c-bus@200 {
		#address-cells = <1>;
		#size-cells = <0>;
		#interrupt-cells = <1>;
		reg = <0x200 0x80>, <0xC60 0x20>;
		compatible = "aspeed,ast2600-i2c-bus";
		clocks = <&syscon ASPEED_CLK_APB2>;
		resets = <&syscon ASPEED_RESET_I2C>;
		interrupts = <GIC_SPI 113 IRQ_TYPE_LEVEL_HIGH>;
		bus-frequency = <100000>;
		buff-mode;
		pinctrl-names = "default";
		pinctrl-0 = <&pinctrl_i2c4_default>;
		status = "disabled";
	};

	i2c4: i2c-bus@280 {
		#address-cells = <1>;
		#size-cells = <0>;
		#interrupt-cells = <1>;
		reg = <0x280 0x80>, <0xC80 0x20>;
		compatible = "aspeed,ast2600-i2c-bus";
		clocks = <&syscon ASPEED_CLK_APB2>;
		resets = <&syscon ASPEED_RESET_I2C>;
		interrupts = <GIC_SPI 114 IRQ_TYPE_LEVEL_HIGH>;
		bus-frequency = <100000>;
		buff-mode;
		pinctrl-names = "default";
		pinctrl-0 = <&pinctrl_i2c5_default>;
		status = "disabled";
	};

	i2c5: i2c-bus@300 {
		#address-cells = <1>;
		#size-cells = <0>;
		#interrupt-cells = <1>;
		reg = <0x300 0x80>, <0xCA0 0x20>;
		compatible = "aspeed,ast2600-i2c-bus";
		clocks = <&syscon ASPEED_CLK_APB2>;
		resets = <&syscon ASPEED_RESET_I2C>;
		interrupts = <GIC_SPI 115 IRQ_TYPE_LEVEL_HIGH>;
		bus-frequency = <100000>;
		buff-mode;
		pinctrl-names = "default";
		pinctrl-0 = <&pinctrl_i2c6_default>;
		status = "disabled";
	};

	i2c6: i2c-bus@380 {
		#address-cells = <1>;
		#size-cells = <0>;
		#interrupt-cells = <1>;
		reg = <0x380 0x80>, <0xCC0 0x20>;
		compatible = "aspeed,ast2600-i2c-bus";
		clocks = <&syscon ASPEED_CLK_APB2>;
		resets = <&syscon ASPEED_RESET_I2C>;
		interrupts = <GIC_SPI 116 IRQ_TYPE_LEVEL_HIGH>;
		bus-frequency = <100000>;
		buff-mode;
		pinctrl-names = "default";
		pinctrl-0 = <&pinctrl_i2c7_default>;
		status = "disabled";
	};

	i2c7: i2c-bus@400 {
		#address-cells = <1>;
		#size-cells = <0>;
		#interrupt-cells = <1>;
		reg = <0x400 0x80>, <0xCE0 0x20>;
		compatible = "aspeed,ast2600-i2c-bus";
		clocks = <&syscon ASPEED_CLK_APB2>;
		resets = <&syscon ASPEED_RESET_I2C>;
		interrupts = <GIC_SPI 117 IRQ_TYPE_LEVEL_HIGH>;
		bus-frequency = <100000>;
		buff-mode;
		pinctrl-names = "default";
		pinctrl-0 = <&pinctrl_i2c8_default>;
		status = "disabled";
	};

	i2c8: i2c-bus@480 {
		#address-cells = <1>;
		#size-cells = <0>;
		#interrupt-cells = <1>;
		reg = <0x480 0x80>, <0xD00 0x20>;
		compatible = "aspeed,ast2600-i2c-bus";
		clocks = <&syscon ASPEED_CLK_APB2>;
		resets = <&syscon ASPEED_RESET_I2C>;
		interrupts = <GIC_SPI 118 IRQ_TYPE_LEVEL_HIGH>;
		bus-frequency = <100000>;
		buff-mode;
		pinctrl-names = "default";
		pinctrl-0 = <&pinctrl_i2c9_default>;
		status = "disabled";
	};

	i2c9: i2c-bus@500 {
		#address-cells = <1>;
		#size-cells = <0>;
		#interrupt-cells = <1>;
		reg = <0x500 0x80>, <0xD20 0x20>;
		compatible = "aspeed,ast2600-i2c-bus";
		clocks = <&syscon ASPEED_CLK_APB2>;
		resets = <&syscon ASPEED_RESET_I2C>;
		interrupts = <GIC_SPI 119 IRQ_TYPE_LEVEL_HIGH>;
		bus-frequency = <100000>;
		buff-mode;
		pinctrl-names = "default";
		pinctrl-0 = <&pinctrl_i2c10_default>;
		status = "disabled";
	};

	i2c10: i2c-bus@580 {
		#address-cells = <1>;
		#size-cells = <0>;
		#interrupt-cells = <1>;
		reg = <0x580 0x80>, <0xD40 0x20>;
		compatible = "aspeed,ast2600-i2c-bus";
		clocks = <&syscon ASPEED_CLK_APB2>;
		resets = <&syscon ASPEED_RESET_I2C>;
		interrupts = <GIC_SPI 120 IRQ_TYPE_LEVEL_HIGH>;
		bus-frequency = <100000>;
		buff-mode;
		pinctrl-names = "default";
		pinctrl-0 = <&pinctrl_i2c11_default>;
		status = "disabled";
	};

	i2c11: i2c-bus@600 {
		#address-cells = <1>;
		#size-cells = <0>;
		#interrupt-cells = <1>;
		reg = <0x600 0x80>, <0xD60 0x20>;
		compatible = "aspeed,ast2600-i2c-bus";
		clocks = <&syscon ASPEED_CLK_APB2>;
		resets = <&syscon ASPEED_RESET_I2C>;
		interrupts = <GIC_SPI 121 IRQ_TYPE_LEVEL_HIGH>;
		bus-frequency = <100000>;
		buff-mode;
		pinctrl-names = "default";
		pinctrl-0 = <&pinctrl_i2c12_default>;
		status = "disabled";
	};

	i2c12: i2c-bus@680 {
		#address-cells = <1>;
		#size-cells = <0>;
		#interrupt-cells = <1>;
		reg = <0x680 0x80>, <0xD80 0x20>;
		compatible = "aspeed,ast2600-i2c-bus";
		clocks = <&syscon ASPEED_CLK_APB2>;
		resets = <&syscon ASPEED_RESET_I2C>;
		interrupts = <GIC_SPI 122 IRQ_TYPE_LEVEL_HIGH>;
		bus-frequency = <100000>;
		buff-mode;
		pinctrl-names = "default";
		pinctrl-0 = <&pinctrl_i2c13_default>;
		status = "disabled";
	};

	i2c13: i2c-bus@700 {
		#address-cells = <1>;
		#size-cells = <0>;
		#interrupt-cells = <1>;
		reg = <0x700 0x80>, <0xDA0 0x20>;
		compatible = "aspeed,ast2600-i2c-bus";
		clocks = <&syscon ASPEED_CLK_APB2>;
		resets = <&syscon ASPEED_RESET_I2C>;
		interrupts = <GIC_SPI 123 IRQ_TYPE_LEVEL_HIGH>;
		bus-frequency = <100000>;
		buff-mode;
		pinctrl-names = "default";
		pinctrl-0 = <&pinctrl_i2c14_default>;
		status = "disabled";
	};

	i2c14: i2c-bus@780 {
		#address-cells = <1>;
		#size-cells = <0>;
		#interrupt-cells = <1>;
		reg = <0x780 0x80>, <0xDC0 0x20>;
		compatible = "aspeed,ast2600-i2c-bus";
		clocks = <&syscon ASPEED_CLK_APB2>;
		resets = <&syscon ASPEED_RESET_I2C>;
		interrupts = <GIC_SPI 124 IRQ_TYPE_LEVEL_HIGH>;
		bus-frequency = <100000>;
		buff-mode;
		pinctrl-names = "default";
		pinctrl-0 = <&pinctrl_i2c15_default>;
		status = "disabled";
	};

	i2c15: i2c-bus@800 {
		#address-cells = <1>;
		#size-cells = <0>;
		#interrupt-cells = <1>;
		reg = <0x800 0x80>, <0xDE0 0x20>;
		compatible = "aspeed,ast2600-i2c-bus";
		clocks = <&syscon ASPEED_CLK_APB2>;
		resets = <&syscon ASPEED_RESET_I2C>;
		interrupts = <GIC_SPI 125 IRQ_TYPE_LEVEL_HIGH>;
		bus-frequency = <100000>;
		buff-mode;
		pinctrl-names = "default";
		pinctrl-0 = <&pinctrl_i2c16_default>;
		status = "disabled";
	};
};

&i2csec {

	i2c_gr0: i2c-global-regs@0 {
		compatible = "aspeed,ast2600-i2c-global", "syscon";
		reg = <0x0 0x20>;
		clocks = <&syscon ASPEED_CLK_APB2>;
		status = "disabled";
	};

	i2c16: i2c-bus@80 {
		#address-cells = <1>;
		#size-cells = <0>;
		#interrupt-cells = <1>;
		reg = <0x80 0x80>, <0xC00 0x20>;
		compatible = "aspeed,ast2600-i2c-bus";
		clocks = <&syscon ASPEED_CLK_APB2>;
		interrupts = <GIC_SPI 75 IRQ_TYPE_LEVEL_HIGH>;
		bus-frequency = <100000>;
		pinctrl-names = "default";
		pinctrl-0 = <&pinctrl_si2c1_default>;
		buff-mode;
		status = "disabled";
	};

	i2c17: i2c-bus@100 {
		#address-cells = <1>;
		#size-cells = <0>;
		#interrupt-cells = <1>;
		reg = <0x100 0x80>, <0xC20 0x20>;
		compatible = "aspeed,ast2600-i2c-bus";
		clocks = <&syscon ASPEED_CLK_APB2>;
		interrupts = <GIC_SPI 76 IRQ_TYPE_LEVEL_HIGH>;
		bus-frequency = <100000>;
		pinctrl-names = "default";
		pinctrl-0 = <&pinctrl_si2c2_default>;
		buff-mode;
		status = "disabled";
	};

	i2c18: i2c-bus@180 {
		#address-cells = <1>;
		#size-cells = <0>;
		#interrupt-cells = <1>;
		reg = <0x180 0x80>, <0xC40 0x20>;
		compatible = "aspeed,ast2600-i2c-bus";
		clocks = <&syscon ASPEED_CLK_APB2>;
		interrupts = <GIC_SPI 77 IRQ_TYPE_LEVEL_HIGH>;
		bus-frequency = <100000>;
		pinctrl-names = "default";
		pinctrl-0 = <&pinctrl_si2c3_default>;
		buff-mode;
		status = "disabled";
	};

	i2c19: i2c-bus@200 {
		#address-cells = <1>;
		#size-cells = <0>;
		#interrupt-cells = <1>;
		reg = <0x200 0x80>, <0xC60 0x20>;
		compatible = "aspeed,ast2600-i2c-bus";
		clocks = <&syscon ASPEED_CLK_APB2>;
		interrupts = <GIC_SPI 78 IRQ_TYPE_LEVEL_HIGH>;
		bus-frequency = <100000>;
		pinctrl-names = "default";
		pinctrl-0 = <&pinctrl_si2c4_default>;
		buff-mode;
		status = "disabled";
	};

};

&i3c{
	i3cglobal: i3cg@00 {
		reg = <0x0 0x1000>;
		compatible = "aspeed,ast2600-i3c-global", "syscon";
		resets = <&syscon ASPEED_RESET_I3C>;
		num-i3cs = <6>;
		pull-up-resistors = <2000 2000 2000 2000 2000 2000>;
	};

	i3c0: i3c0@2000 {
		#address-cells = <1>;
		#size-cells = <0>;
		#interrupt-cells = <1>;

		i3c_chan = <0>;
		reg = <0x2000 0x1000>;
		compatible = "aspeed,ast2600-i3c", "syscon";
		clocks = <&syscon ASPEED_CLK_GATE_I3C0CLK>;
		resets = <&syscon ASPEED_RESET_I3C0>;
		i2c-scl-hz = <1000000>;
		i3c-scl-hz = <12500000>;
		sda-tx-hold-ns = <10>;
		timed-reset-scl-low-ns = <52428800>;
		i3c-pp-scl-hi-period-ns = <40>;
		i3c-pp-scl-lo-period-ns = <40>;
		i3c-od-scl-hi-period-ns = <380>;
		i3c-od-scl-lo-period-ns = <620>;
		interrupts = <GIC_SPI 102 IRQ_TYPE_LEVEL_HIGH>;
		pinctrl-names = "default";
		pinctrl-0 = <&pinctrl_i3c1_default>;
		aspeed,scu = <&syscon>;
		aspeed,i3cg = <&i3cglobal>;

		status = "disabled";
	};

	i3c1: i3c1@3000 {
		#address-cells = <1>;
		#size-cells = <0>;
		#interrupt-cells = <1>;

		i3c_chan = <1>;
		reg = <0x3000 0x1000>;
		compatible = "aspeed,ast2600-i3c", "syscon";
		clocks = <&syscon ASPEED_CLK_GATE_I3C1CLK>;
		resets = <&syscon ASPEED_RESET_I3C1>;
		i2c-scl-hz = <1000000>;
		i3c-scl-hz = <12500000>;
		sda-tx-hold-ns = <10>;
		timed-reset-scl-low-ns = <52428800>;
		i3c-pp-scl-hi-period-ns = <40>;
		i3c-pp-scl-lo-period-ns = <40>;
		i3c-od-scl-hi-period-ns = <380>;
		i3c-od-scl-lo-period-ns = <620>;
		interrupts = <GIC_SPI 103 IRQ_TYPE_LEVEL_HIGH>;
		pinctrl-names = "default";
		pinctrl-0 = <&pinctrl_i3c2_default>;
		aspeed,scu = <&syscon>;
		aspeed,i3cg = <&i3cglobal>;

		status = "disabled";
	};

	i3c2: i3c2@4000 {
		#address-cells = <1>;
		#size-cells = <0>;
		#interrupt-cells = <1>;

		i3c_chan = <2>;
		reg = <0x4000 0x1000>;
		compatible = "aspeed,ast2600-i3c", "syscon";
		clocks = <&syscon ASPEED_CLK_GATE_I3C2CLK>;
		resets = <&syscon ASPEED_RESET_I3C2>;
		i2c-scl-hz = <1000000>;
		i3c-scl-hz = <12500000>;
		sda-tx-hold-ns = <10>;
		timed-reset-scl-low-ns = <52428800>;
		i3c-pp-scl-hi-period-ns = <40>;
		i3c-pp-scl-lo-period-ns = <40>;
		i3c-od-scl-hi-period-ns = <380>;
		i3c-od-scl-lo-period-ns = <620>;
		interrupts = <GIC_SPI 104 IRQ_TYPE_LEVEL_HIGH>;
		aspeed,scu = <&syscon>;
		aspeed,i3cg = <&i3cglobal>;

		status = "disabled";
	};

	i3c3: i3c3@5000 {
		#address-cells = <1>;
		#size-cells = <0>;
		#interrupt-cells = <1>;

		i3c_chan = <3>;
		reg = <0x5000 0x1000>;
		compatible = "aspeed,ast2600-i3c", "syscon";
		clocks = <&syscon ASPEED_CLK_GATE_I3C3CLK>;
		resets = <&syscon ASPEED_RESET_I3C3>;
		i2c-scl-hz = <1000000>;
		i3c-scl-hz = <12500000>;
		sda-tx-hold-ns = <10>;
		timed-reset-scl-low-ns = <52428800>;
		i3c-pp-scl-hi-period-ns = <40>;
		i3c-pp-scl-lo-period-ns = <40>;
		i3c-od-scl-hi-period-ns = <380>;
		i3c-od-scl-lo-period-ns = <620>;
		interrupts = <GIC_SPI 105 IRQ_TYPE_LEVEL_HIGH>;
		aspeed,scu = <&syscon>;
		aspeed,i3cg = <&i3cglobal>;

		status = "disabled";
	};

	i3c4: i3c4@6000 {
		#address-cells = <1>;
		#size-cells = <0>;
		#interrupt-cells = <1>;

		i3c_chan = <4>;
		reg = <0x6000 0x1000>;
		compatible = "aspeed,ast2600-i3c", "syscon";
		clocks = <&syscon ASPEED_CLK_GATE_I3C4CLK>;
		resets = <&syscon ASPEED_RESET_I3C4>;
		i2c-scl-hz = <1000000>;
		i3c-scl-hz = <12500000>;
		sda-tx-hold-ns = <10>;
		timed-reset-scl-low-ns = <52428800>;
		i3c-pp-scl-hi-period-ns = <40>;
		i3c-pp-scl-lo-period-ns = <40>;
		i3c-od-scl-hi-period-ns = <380>;
		i3c-od-scl-lo-period-ns = <620>;
		interrupts = <GIC_SPI 106 IRQ_TYPE_LEVEL_HIGH>;
		pinctrl-names = "default";
		pinctrl-0 = <&pinctrl_i3c5_default>;
		aspeed,scu = <&syscon>;
		aspeed,i3cg = <&i3cglobal>;

		status = "disabled";
	};

	i3c5: i3c5@7000 {
		#address-cells = <1>;
		#size-cells = <0>;
		#interrupt-cells = <1>;

		i3c_chan = <5>;
		reg = <0x7000 0x1000>;
		compatible = "aspeed,ast2600-i3c", "syscon";
		clocks = <&syscon ASPEED_CLK_GATE_I3C5CLK>;
		resets = <&syscon ASPEED_RESET_I3C5>;
		i2c-scl-hz = <1000000>;
		i3c-scl-hz = <12500000>;
		sda-tx-hold-ns = <10>;
		timed-reset-scl-low-ns = <52428800>;
		i3c-pp-scl-hi-period-ns = <40>;
		i3c-pp-scl-lo-period-ns = <40>;
		i3c-od-scl-hi-period-ns = <380>;
		i3c-od-scl-lo-period-ns = <620>;
		interrupts = <GIC_SPI 107 IRQ_TYPE_LEVEL_HIGH>;
		pinctrl-names = "default";
		pinctrl-0 = <&pinctrl_i3c6_default>;
		aspeed,scu = <&syscon>;
		aspeed,i3cg = <&i3cglobal>;

		status = "disabled";
	};

};
